# MCXA156 register map
Vendor: nxp.com; File version: 1.0
CPU: CM33 r2p0, little endian, no MPU, FPU, VTOR, 3 interrupt priority bits
Registers are 32-bit, read-write, reset 0x0 unless marked. A register's access mark holds for its fields unless they carry their own. Offsets are from the block's base; [hi:lo] are bit positions; {n}, {i} and the like mark numbered series; 'fields as' and 'values as' point back to an identical list.

## PORT2 — PORT
Base 0x400BE000
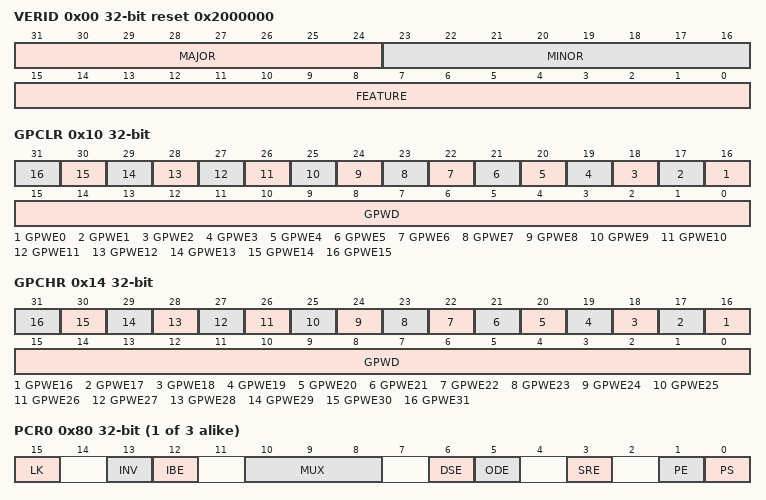
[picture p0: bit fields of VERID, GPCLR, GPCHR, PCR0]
0x00 VERID ro reset 0x2000000 — Version ID
  [31:24] MAJOR — Major Version Number
  [23:16] MINOR — Minor Version Number
  [15:0] FEATURE — Feature Specification Number
    0=Basic implementation
0x10 GPCLR — Global Pin Control Low
  [n+16] GPWE{n} (n=0..15) — Global Pin Write Enable
    0=gpwe0 (Not updated); 1=gpwe1 (Updated)
  [15:0] GPWD — Global Pin Write Data
0x14 GPCHR — Global Pin Control High
  [n] GPWE{n} (n=16..31) — Global Pin Write Enable
    0=gpwe0 (Not updated); 1=gpwe1 (Updated)
  [15:0] GPWD — Global Pin Write Data
0x20 CONFIG — Configuration
  [0] RANGE — Port Voltage Range
    0=1.71 V-3.6 V; 1=2.70 V-3.6 V
{0x80+4i} PCR{i} (i=0..2) — Pin Control {i}
  [15] LK — Lock Register
    0=Does not lock; 1=Locks
  [13] INV — Invert Input
    0=Does not invert; 1=Inverts
  [12] IBE — Input Buffer Enable
    0=Disables; 1=Enables
  [10:8] MUX — Pin Multiplex Control
    0=Alternative 0 (GPIO); {v}=Alternative {v} (chip-specific) (v=1..7)
  [6] DSE — Drive Strength Enable
    0=Low; 1=High
  [5] ODE — Open Drain Enable
    0=Disables; 1=Enables
  [3] SRE — Slew Rate Enable
    0=Fast; 1=Slow
  [1] PE — Pull Enable
    0=Disables; 1=Enables
  [0] PS — Pull Select
    0=Enables internal pulldown resistor; 1=Enables internal pullup resistor
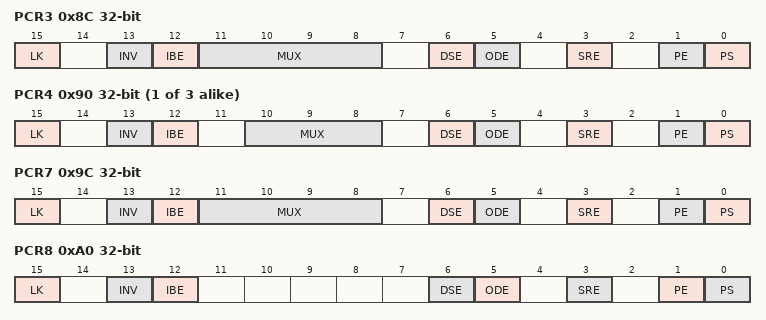
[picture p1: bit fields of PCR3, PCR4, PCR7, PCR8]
0x8C PCR3 — Pin Control 3
  [15] LK — Lock Register
    0=Does not lock; 1=Locks
  [13] INV — Invert Input
    0=Does not invert; 1=Inverts
  [12] IBE — Input Buffer Enable
    0=Disables; 1=Enables
  [11:8] MUX — Pin Multiplex Control
    0=Alternative 0 (GPIO); {v}=Alternative {v} (chip-specific) (v=1..13)
  [6] DSE — Drive Strength Enable
    0=Low; 1=High
  [5] ODE — Open Drain Enable
    0=Disables; 1=Enables
  [3] SRE — Slew Rate Enable
    0=Fast; 1=Slow
  [1] PE — Pull Enable
    0=Disables; 1=Enables
  [0] PS — Pull Select
    values as PCR0.PS
{0x80+4i} PCR{i} (i=4..6) — Pin Control {i}
  fields as PCR0
0x9C PCR7 — Pin Control 7
  fields as PCR3
0xA0 PCR8 — Pin Control 8
  [15] LK — Lock Register
    0=Does not lock; 1=Locks
  [13] INV — Invert Input
    0=Does not invert; 1=Inverts
  [12] IBE — Input Buffer Enable
    0=Disables; 1=Enables
  [6] DSE — Drive Strength Enable
    0=Low; 1=High
  [5] ODE — Open Drain Enable
    0=Disables; 1=Enables
  [3] SRE — Slew Rate Enable
    0=Fast; 1=Slow
  [1] PE — Pull Enable
    0=Disables; 1=Enables
  [0] PS — Pull Select
    values as PCR0.PS
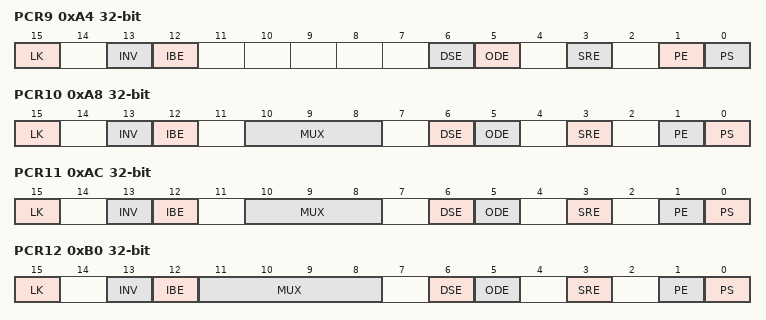
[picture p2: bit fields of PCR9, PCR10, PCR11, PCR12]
0xA4 PCR9 — Pin Control 9
  fields as PCR8
0xA8 PCR10 — Pin Control 10
  fields as PCR0
0xAC PCR11 — Pin Control 11
  fields as PCR0
0xB0 PCR12 — Pin Control 12
  fields as PCR3
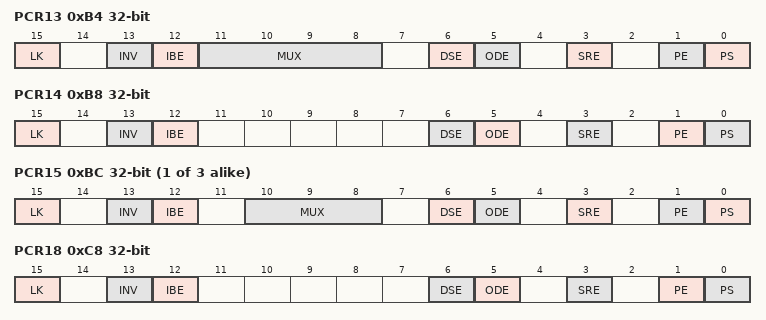
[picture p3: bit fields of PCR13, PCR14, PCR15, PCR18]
0xB4 PCR13 — Pin Control 13
  fields as PCR3
0xB8 PCR14 — Pin Control 14
  fields as PCR8
{0x80+4i} PCR{i} (i=15..17) — Pin Control {i}
  fields as PCR0
0xC8 PCR18 — Pin Control 18
  fields as PCR8
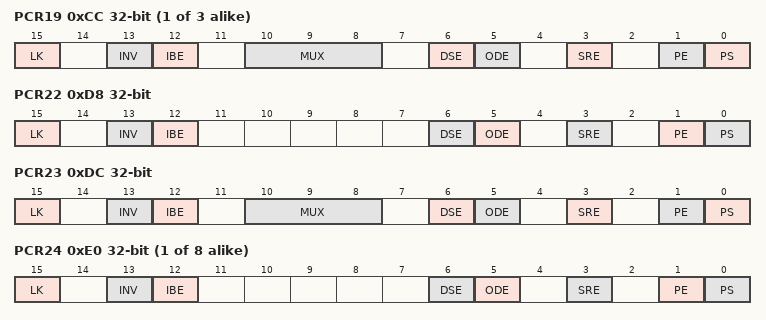
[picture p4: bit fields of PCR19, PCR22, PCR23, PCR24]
{0x80+4i} PCR{i} (i=19..21) — Pin Control {i}
  fields as PCR0
0xD8 PCR22 — Pin Control 22
  fields as PCR8
0xDC PCR23 — Pin Control 23
  fields as PCR0
{0x80+4i} PCR{i} (i=24..31) — Pin Control {i}
  fields as PCR8

## CDOG
Base 0x40100000
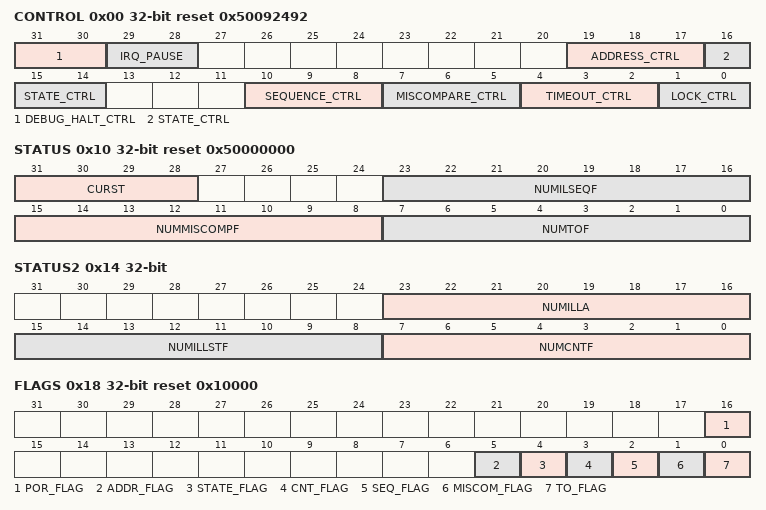
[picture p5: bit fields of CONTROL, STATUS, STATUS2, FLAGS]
0x00 CONTROL reset 0x50092492
  [31:30] DEBUG_HALT_CTRL — DEBUG_HALT control
    1=RUN_TIMER (Keep the timer running); 2=PAUSE_TIMER (Stop the timer)
  [29:28] IRQ_PAUSE — IRQ pause control
    values as DEBUG_HALT_CTRL
  [19:17] ADDRESS_CTRL — ADDRESS fault control
    1=ENABLE_RESET; 2=ENABLE_INTERRUPT; 4=DISABLE_BOTH (Disable both reset and interrupt)
  [16:14] STATE_CTRL — STATE fault control
    values as ADDRESS_CTRL
  [10:8] SEQUENCE_CTRL — SEQUENCE fault control
    values as ADDRESS_CTRL
  [7:5] MISCOMPARE_CTRL — MISCOMPARE fault control
    values as ADDRESS_CTRL
  [4:2] TIMEOUT_CTRL — TIMEOUT fault control
    values as ADDRESS_CTRL
  [1:0] LOCK_CTRL — Lock control
    1=LOCKED; 2=UNLOCKED
0x04 RELOAD reset 0xFFFFFFFF — Instruction Timer Reload Register
  [31:0] RLOAD — Instruction Timer reload value
0x08 INSTRUCTION_TIMER ro reset 0xFFFFFFFF
  [31:0] INSTIM — Current value of the Instruction Timer
0x10 STATUS ro reset 0x50000000 — Status 1 Register
  [31:28] CURST — Current State
  [23:16] NUMILSEQF — Number of SEQUENCE faults since the last POR
  [15:8] NUMMISCOMPF — Number of MISCOMPARE faults since the last POR
  [7:0] NUMTOF — Number of TIMEOUT faults since the last POR
0x14 STATUS2 ro
  [23:16] NUMILLA — Number of ADDRESS faults since the last POR
  [15:8] NUMILLSTF — Number of STATE faults since the last POR
  [7:0] NUMCNTF — Number of CONTROL faults since the last POR
0x18 FLAGS reset 0x10000 write-1-clears
  [16] POR_FLAG write-1-clears — Power-on reset flag
    0=NO_FLAG (A Power-on reset event has not occurred); 1=FLAG (A Power-on reset event has occurred)
  [5] ADDR_FLAG write-1-clears — ADDRESS fault flag
    0=NO_FLAG (An ADDRESS fault has not occurred); 1=FLAG (An ADDRESS fault has occurred)
  [4] STATE_FLAG write-1-clears — STATE fault flag
    0=NO_FLAG (A STATE fault has not occurred); 1=FLAG (A STATE fault has occurred)
  [3] CNT_FLAG write-1-clears — CONTROL fault flag
    0=NO_FLAG (A CONTROL fault has not occurred); 1=FLAG (A CONTROL fault has occurred)
  [2] SEQ_FLAG write-1-clears — SEQUENCE fault flag
    0=NO_FLAG (A SEQUENCE fault has not occurred); 1=FLAG (A SEQUENCE fault has occurred)
  [1] MISCOM_FLAG write-1-clears — MISCOMPARE fault flag
    0=NO_FLAG (A MISCOMPARE fault has not occurred); 1=FLAG (A MISCOMPARE fault has occurred)
  [0] TO_FLAG write-1-clears — TIMEOUT fault flag
    0=NO_FLAG (A TIMEOUT fault has not occurred); 1=FLAG (A TIMEOUT fault has occurred)
0x1C PERSISTENT — Persistent Data Storage Register
  [31:0] PERSIS — Persistent Storage
0x20 START wo — START Command Register
  [31:0] STRT — Start command
0x24 STOP wo — STOP Command Register
  [31:0] STP — Stop command
0x28 RESTART wo — RESTART Command Register
  [31:0] RSTRT — Restart command
0x2C ADD wo — ADD Command Register
  [31:0] AD — ADD Write Value
0x30 ADD1 wo — ADD1 Command Register
  [31:0] AD1 — ADD 1
0x34 ADD16 wo — ADD16 Command Register
  [31:0] AD16 — ADD 16
0x38 ADD256 wo — ADD256 Command Register
  [31:0] AD256 — ADD 256
0x3C SUB wo — SUB Command Register
  [31:0] SB — Subtract Write Value
0x40 SUB1 wo — SUB1 Command Register
  [31:0] SB1 — Subtract 1
0x44 SUB16 wo — SUB16 Command Register
  [31:0] SB16 — Subtract 16
0x48 SUB256 wo — SUB256 Command Register
  [31:0] SB256 — Subtract 256
0x4C ASSERT16 wo — ASSERT16 Command Register
  [31:0] AST16 — ASSERT16 Command
